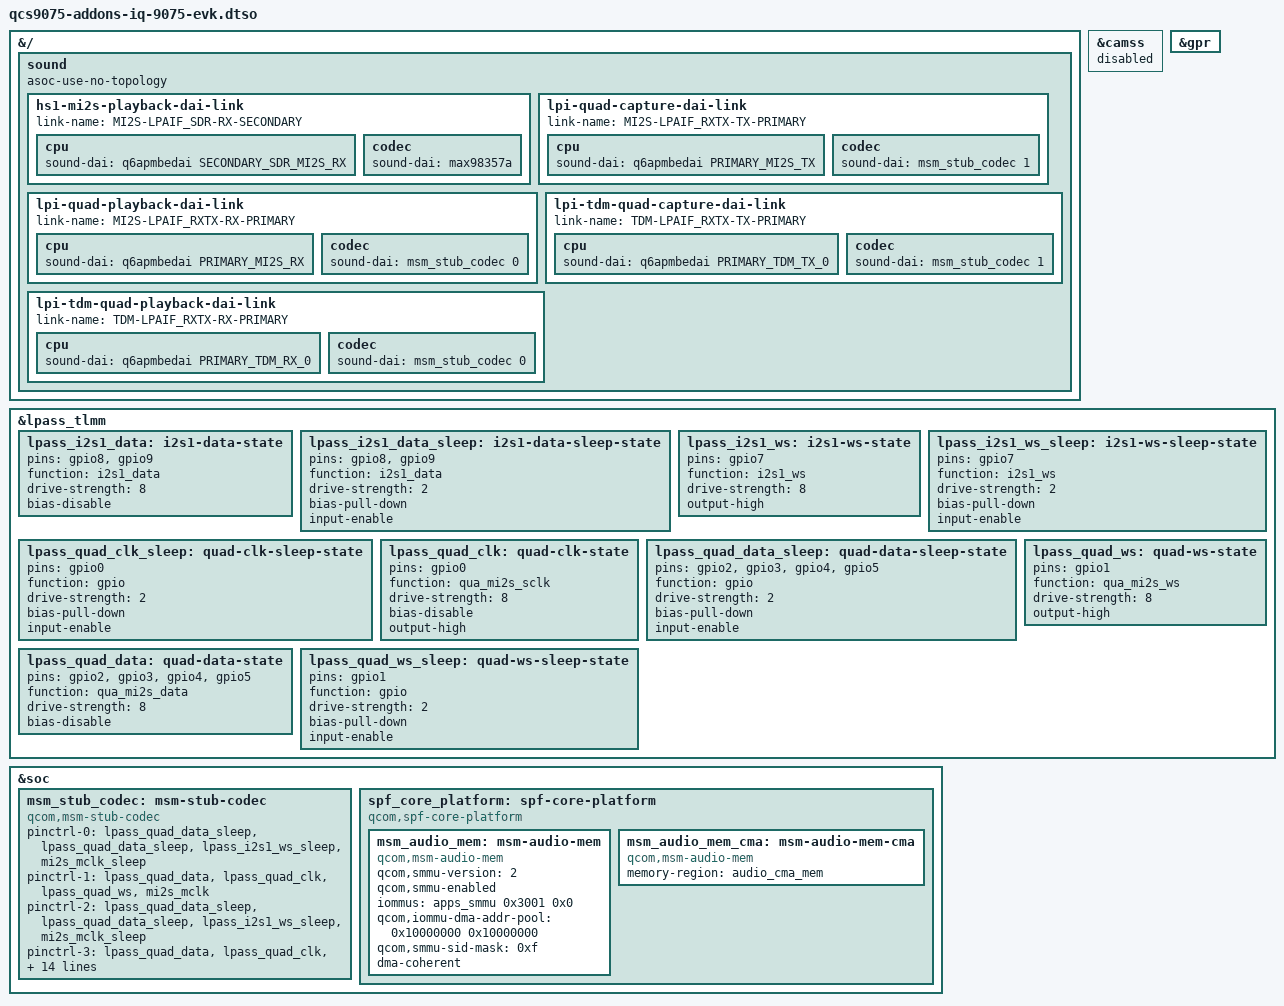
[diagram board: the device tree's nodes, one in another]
// SPDX-License-Identifier: BSD-3-Clause
/*
 * Copyright (c) 2024-2025, Qualcomm Innovation Center, Inc. All rights reserved.
 */
/dts-v1/;
/plugin/;

#include "sa8775p-addons.dtsi"

&{/} {
	sound {
		asoc-use-no-topology;
		hs1-mi2s-playback-dai-link {
			link-name = "MI2S-LPAIF_SDR-RX-SECONDARY";

			cpu {
				sound-dai = <&q6apmbedai SECONDARY_SDR_MI2S_RX>;
			};

			codec {
				sound-dai = <&max98357a>;
			};
		};

		lpi-quad-capture-dai-link {
			link-name = "MI2S-LPAIF_RXTX-TX-PRIMARY";

			cpu {
				sound-dai = <&q6apmbedai PRIMARY_MI2S_TX>;
			};

			codec {
				sound-dai = <&msm_stub_codec 1>;
			};
		};

		lpi-quad-playback-dai-link {
			link-name = "MI2S-LPAIF_RXTX-RX-PRIMARY";

			cpu {
				sound-dai = <&q6apmbedai PRIMARY_MI2S_RX>;
			};

			codec {
				sound-dai = <&msm_stub_codec 0>;
			};
		};

		lpi-tdm-quad-capture-dai-link {
			link-name = "TDM-LPAIF_RXTX-TX-PRIMARY";

			cpu {
				sound-dai = <&q6apmbedai PRIMARY_TDM_TX_0>;
			};

			codec {
				sound-dai = <&msm_stub_codec 1>;
			};
		};

		lpi-tdm-quad-playback-dai-link {
			link-name = "TDM-LPAIF_RXTX-RX-PRIMARY";

			cpu {
				sound-dai = <&q6apmbedai PRIMARY_TDM_RX_0>;
			};

			codec {
				sound-dai = <&msm_stub_codec 0>;
			};
		};
	};
};

&camss {
	status = "disabled";
};

&gpr {
	status = "okay";
};

&lpass_tlmm {
	lpass_i2s1_data: i2s1-data-state {
			pins = "gpio8", "gpio9";
			function = "i2s1_data";
			drive-strength = <8>;
			bias-disable;
	};

	lpass_i2s1_data_sleep: i2s1-data-sleep-state {
			pins = "gpio8", "gpio9";
			function = "i2s1_data";
			drive-strength = <2>;
			bias-pull-down;
			input-enable;
	};

	lpass_i2s1_ws: i2s1-ws-state {
			pins = "gpio7";
			function = "i2s1_ws";
			drive-strength = <8>;
			output-high;
	};

	lpass_i2s1_ws_sleep: i2s1-ws-sleep-state {
			pins = "gpio7";
			function = "i2s1_ws";
			drive-strength = <2>;
			bias-pull-down;
			input-enable;
	};

	lpass_quad_clk_sleep: quad-clk-sleep-state {
			pins = "gpio0";
			function = "gpio";
			drive-strength = <2>;
			bias-pull-down;
			input-enable;
	};

	lpass_quad_clk: quad-clk-state {
			pins = "gpio0";
			function = "qua_mi2s_sclk";
			drive-strength = <8>;
			bias-disable;
			output-high;
	};

	lpass_quad_data_sleep: quad-data-sleep-state {
			pins = "gpio2", "gpio3", "gpio4", "gpio5";
			function = "gpio";
			drive-strength = <2>;
			bias-pull-down;
			input-enable;
	};

	lpass_quad_data: quad-data-state {
			pins = "gpio2", "gpio3", "gpio4", "gpio5";
			function = "qua_mi2s_data";
			drive-strength = <8>;
			bias-disable;
	};

	lpass_quad_ws_sleep: quad-ws-sleep-state {
			pins = "gpio1";
			function = "gpio";
			drive-strength = <2>;
			bias-pull-down;
			input-enable;
	};

	lpass_quad_ws: quad-ws-state {
			pins = "gpio1";
			function = "qua_mi2s_ws";
			drive-strength = <8>;
			output-high;
	};
};

&soc {
	msm_stub_codec: msm-stub-codec {
		compatible = "qcom,msm-stub-codec";

                pinctrl-names = "default", "stub_aif0_active", "stub_aif0_sleep",
				"stub_aif1_active", "stub_aif1_sleep", "stub_aif2_active",
				"stub_aif2_sleep", "stub_aif3_active", "stub_aif3_sleep";
		pinctrl-0 = <&lpass_quad_data_sleep>, <&lpass_quad_data_sleep>,
                            <&lpass_i2s1_ws_sleep>, <&mi2s_mclk_sleep>;
		pinctrl-1 = <&lpass_quad_data>, <&lpass_quad_clk>, <&lpass_quad_ws>,
                            <&mi2s_mclk>;
		pinctrl-2 = <&lpass_quad_data_sleep>, <&lpass_quad_data_sleep>,
                            <&lpass_i2s1_ws_sleep>, <&mi2s_mclk_sleep>;
		pinctrl-3 = <&lpass_quad_data>, <&lpass_quad_clk>, <&lpass_quad_ws>,
                            <&mi2s_mclk>;
		pinctrl-4 = <&lpass_quad_data_sleep>, <&lpass_quad_data_sleep>,
                            <&lpass_i2s1_ws_sleep>, <&mi2s_mclk_sleep>;
		pinctrl-5 = <&lpass_quad_data>, <&lpass_quad_clk>, <&lpass_quad_ws>,
                            <&mi2s_mclk>;
		pinctrl-6 = <&lpass_quad_data_sleep>, <&lpass_quad_data_sleep>,
                            <&lpass_i2s1_ws_sleep>, <&mi2s_mclk_sleep>;
		pinctrl-7 = <&lpass_quad_data>, <&lpass_quad_clk>, <&lpass_quad_ws>,
                            <&mi2s_mclk>;
		pinctrl-8 = <&lpass_quad_data_sleep>, <&lpass_quad_data_sleep>,
                            <&lpass_i2s1_ws_sleep>, <&mi2s_mclk_sleep>;

		#sound-dai-cells = <1>;
	};

	spf_core_platform: spf-core-platform {
		compatible = "qcom,spf-core-platform";

		msm_audio_mem: msm-audio-mem {
			compatible = "qcom,msm-audio-mem";
			qcom,smmu-version = <2>;
			qcom,smmu-enabled;
			iommus = <&apps_smmu 0x3001 0x0>;
			qcom,iommu-dma-addr-pool = <0x10000000 0x10000000>;
			qcom,smmu-sid-mask = /bits/ 64 <0xf>;
			dma-coherent;
		};

		msm_audio_mem_cma: msm-audio-mem-cma {
			compatible = "qcom,msm-audio-mem";
			memory-region = <&audio_cma_mem>;
		};
	};
};
